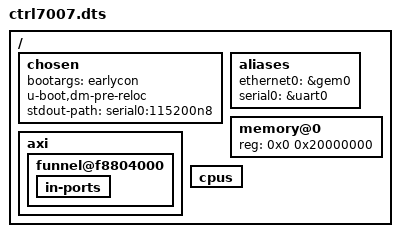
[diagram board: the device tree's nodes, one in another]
/*
 * CAUTION: This file is automatically generated by Xilinx.
 * Version: XSCT 2023.2
 * Today is: Thu Dec 19 18:21:52 2024
 */


/dts-v1/;
#include "zynq-7000.dtsi"
#include "ctrl7007_common.dtsi"
/ {
	chosen {
		bootargs = "earlycon";
    u-boot,dm-pre-reloc;
		stdout-path = "serial0:115200n8";
	};
	aliases {
		ethernet0 = &gem0;
		serial0 = &uart0;
	};
	memory@0 {
		device_type = "memory";
		reg = <0x0 0x20000000>;
	};
	axi {
		funnel@f8804000{
			in-ports{
				/delete-node/ port@1;
			};
		};		
		/delete-node/ ptm@f889d000 ;
	};
	cpus {
		/delete-node/ cpu@1 ;
	};
};
